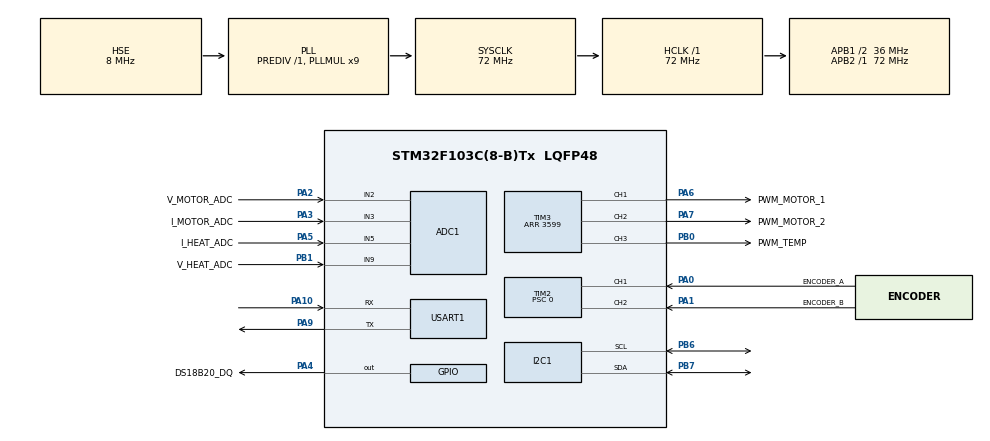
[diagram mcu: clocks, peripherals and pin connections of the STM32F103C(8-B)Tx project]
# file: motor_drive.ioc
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ADC1.Channel-0\#ChannelRegularConversion=ADC_CHANNEL_2
ADC1.Channel-1\#ChannelRegularConversion=ADC_CHANNEL_3
ADC1.Channel-2\#ChannelRegularConversion=ADC_CHANNEL_5
ADC1.Channel-3\#ChannelRegularConversion=ADC_CHANNEL_9
ADC1.ContinuousConvMode=ENABLE
ADC1.NbrOfConversion=4
ADC1.NbrOfConversionFlag=1
ADC1.Rank-0\#ChannelRegularConversion=1
ADC1.Rank-1\#ChannelRegularConversion=2
ADC1.Rank-2\#ChannelRegularConversion=3
ADC1.Rank-3\#ChannelRegularConversion=4
ADC1.SamplingTime-0\#ChannelRegularConversion=ADC_SAMPLETIME_71CYCLES_5
ADC1.SamplingTime-1\#ChannelRegularConversion=ADC_SAMPLETIME_71CYCLES_5
ADC1.SamplingTime-2\#ChannelRegularConversion=ADC_SAMPLETIME_71CYCLES_5
ADC1.SamplingTime-3\#ChannelRegularConversion=ADC_SAMPLETIME_71CYCLES_5
ADC1.master=1
Dma.ADC1.0.Direction=DMA_PERIPH_TO_MEMORY
Dma.ADC1.0.Instance=DMA1_Channel1
Dma.ADC1.0.MemDataAlignment=DMA_MDATAALIGN_HALFWORD
Dma.ADC1.0.MemInc=DMA_MINC_ENABLE
Dma.ADC1.0.Mode=DMA_CIRCULAR
Dma.ADC1.0.PeriphDataAlignment=DMA_PDATAALIGN_HALFWORD
Dma.ADC1.0.PeriphInc=DMA_PINC_DISABLE
Dma.ADC1.0.Priority=DMA_PRIORITY_LOW
Dma.Request0=ADC1
FREERTOS.Tasks01=defaultTask,24,128,StartDefaultTask,Default,NULL,Dynamic,NULL,NULL
FREERTOS.configTOTAL_HEAP_SIZE=8192
I2C1.I2C_Mode=I2C_Fast
Mcu.Family=STM32F1
Mcu.Name=STM32F103C(8-B)Tx
Mcu.Package=LQFP48
NVIC.DMA1_Channel1_IRQn=true\:5\:0\:false\:false\:true\:true\:false\:true\:true
NVIC.I2C1_ER_IRQn=true\:5\:0\:false\:false\:true\:true\:true\:true\:true
NVIC.I2C1_EV_IRQn=true\:5\:0\:false\:false\:true\:true\:true\:true\:true
NVIC.PriorityGroup=NVIC_PRIORITYGROUP_4
NVIC.TIM1_UP_IRQn=true\:15\:0\:false\:false\:true\:false\:false\:true\:true
NVIC.TimeBase=TIM1_UP_IRQn
NVIC.TimeBaseIP=TIM1
PA0-WKUP.GPIO_Label=ENCODER_A
PA0-WKUP.GPIO_PuPd=GPIO_PULLUP
PA0-WKUP.Signal=S_TIM2_CH1_ETR
PA1.GPIO_Label=ENCODER_B
PA1.GPIO_PuPd=GPIO_PULLUP
PA1.Signal=S_TIM2_CH2
PA10.Mode=Asynchronous
PA10.Signal=USART1_RX
PA13.Mode=Serial_Wire
PA13.Signal=SYS_JTMS-SWDIO
PA14.Mode=Serial_Wire
PA14.Signal=SYS_JTCK-SWCLK
PA2.GPIO_Label=V_MOTOR_ADC
PA2.Signal=ADCx_IN2
PA3.GPIO_Label=I_MOTOR_ADC
PA3.Signal=ADCx_IN3
PA4.GPIO_Label=DS18B20_DQ
PA4.GPIO_ModeDefaultOutputPP=GPIO_MODE_OUTPUT_OD
PA4.GPIO_PuPd=GPIO_NOPULL
PA4.GPIO_Speed=GPIO_SPEED_FREQ_MEDIUM
PA4.PinState=GPIO_PIN_SET
PA4.Signal=GPIO_Output
PA5.GPIO_Label=I_HEAT_ADC
PA5.Signal=ADCx_IN5
PA6.GPIO_Label=PWM_MOTOR_1
PA6.Signal=S_TIM3_CH1
PA7.GPIO_Label=PWM_MOTOR_2
PA7.Signal=S_TIM3_CH2
PA9.Mode=Asynchronous
PA9.Signal=USART1_TX
PB0.GPIO_Label=PWM_TEMP
PB0.Signal=S_TIM3_CH3
PB1.GPIO_Label=V_HEAT_ADC
PB1.Signal=ADCx_IN9
PB6.Mode=I2C
PB6.Signal=I2C1_SCL
PB7.Mode=I2C
PB7.Signal=I2C1_SDA
PD0-OSC_IN.Mode=HSE-External-Oscillator
PD0-OSC_IN.Signal=RCC_OSC_IN
PD1-OSC_OUT.Mode=HSE-External-Oscillator
PD1-OSC_OUT.Signal=RCC_OSC_OUT
ProjectManager.HeapSize=0x200
ProjectManager.StackSize=0x400
ProjectManager.TargetToolchain=CMake
RCC.ADCPresc=RCC_ADCPCLK2_DIV6
RCC.AHBFreq_Value=72000000
RCC.APB1CLKDivider=RCC_HCLK_DIV2
RCC.APB1Freq_Value=36000000
RCC.APB1TimFreq_Value=72000000
RCC.APB2Freq_Value=72000000
RCC.APB2TimFreq_Value=72000000
RCC.HCLKFreq_Value=72000000
RCC.PLLMUL=RCC_PLL_MUL9
RCC.PLLSourceVirtual=RCC_PLLSOURCE_HSE
RCC.SYSCLKFreq_VALUE=72000000
RCC.SYSCLKSource=RCC_SYSCLKSOURCE_PLLCLK
RCC.USBFreq_Value=72000000
SH.ADCx_IN2.0=ADC1_IN2,IN2
SH.ADCx_IN3.0=ADC2_IN3
SH.ADCx_IN3.1=ADC1_IN3,IN3
SH.ADCx_IN5.0=ADC1_IN5,IN5
SH.ADCx_IN9.0=ADC1_IN9,IN9
SH.S_TIM2_CH1_ETR.0=TIM2_CH1,Encoder_Interface
SH.S_TIM2_CH2.0=TIM2_CH2,Encoder_Interface
SH.S_TIM3_CH1.0=TIM3_CH1,PWM Generation1 CH1
SH.S_TIM3_CH2.0=TIM3_CH2,PWM Generation2 CH2
SH.S_TIM3_CH3.0=TIM3_CH3,PWM Generation3 CH3
TIM2.EncoderMode=TIM_ENCODERMODE_TI12
TIM2.IC1Filter=6
TIM2.IC2Filter=6
TIM2.Period=65535
TIM2.Prescaler=0
TIM3.Channel-PWM\ Generation1\ CH1=TIM_CHANNEL_1
TIM3.Channel-PWM\ Generation2\ CH2=TIM_CHANNEL_2
TIM3.Channel-PWM\ Generation3\ CH3=TIM_CHANNEL_3
TIM3.Period=3599
USART1.VirtualMode=VM_ASYNC
VP_FREERTOS_VS_CMSIS_V2.Mode=CMSIS_V2
VP_SYS_VS_tim1.Mode=TIM1
board=custom

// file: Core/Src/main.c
/* USER CODE BEGIN Header */
/**
  ******************************************************************************
  * @file           : main.c
  * @brief          : Main program body
  ******************************************************************************
  * @attention
  *
  * Copyright (c) 2026 STMicroelectronics.
  * All rights reserved.
  *
  * This software is licensed under terms that can be found in the LICENSE file
  * in the root directory of this software component.
  * If no LICENSE file comes with this software, it is provided AS-IS.
  *
  ******************************************************************************
  */
/* USER CODE END Header */
#include "main.h"
#include "cmsis_os.h"
#include "adc.h"
#include "dma.h"
#include "i2c.h"
#include "tim.h"
#include "usart.h"
#include "gpio.h"

void SystemClock_Config(void);
void MX_FREERTOS_Init(void);

int main(void)
{

  /* MCU Configuration--------------------------------------------------------*/

  /* Reset of all peripherals, Initializes the Flash interface and the Systick. */
  HAL_Init();

  /* Configure the system clock */
  SystemClock_Config();

  /* Initialize all configured peripherals */
  MX_GPIO_Init();
  MX_DMA_Init();
  MX_I2C1_Init();
  MX_TIM2_Init();
  MX_USART1_UART_Init();
  MX_TIM3_Init();
  MX_ADC1_Init();

  /* Init scheduler */
  osKernelInitialize();  /* Call init function for freertos objects (in cmsis_os2.c) */
  MX_FREERTOS_Init();

  /* Start scheduler */
  osKernelStart();

  /* We should never get here as control is now taken by the scheduler */

  /* Infinite loop */
  while (1)
  {

  }
}

void SystemClock_Config(void)
{
  RCC_OscInitTypeDef RCC_OscInitStruct = {0};
  RCC_ClkInitTypeDef RCC_ClkInitStruct = {0};
  RCC_PeriphCLKInitTypeDef PeriphClkInit = {0};

  /** Initializes the RCC Oscillators according to the specified parameters
  * in the RCC_OscInitTypeDef structure.
  */
  RCC_OscInitStruct.OscillatorType = RCC_OSCILLATORTYPE_HSE;
  RCC_OscInitStruct.HSEState = RCC_HSE_ON;
  RCC_OscInitStruct.HSEPredivValue = RCC_HSE_PREDIV_DIV1;
  RCC_OscInitStruct.HSIState = RCC_HSI_ON;
  RCC_OscInitStruct.PLL.PLLState = RCC_PLL_ON;
  RCC_OscInitStruct.PLL.PLLSource = RCC_PLLSOURCE_HSE;
  RCC_OscInitStruct.PLL.PLLMUL = RCC_PLL_MUL9;
  if (HAL_RCC_OscConfig(&RCC_OscInitStruct) != HAL_OK)
  {
    Error_Handler();
  }

  /** Initializes the CPU, AHB and APB buses clocks
  */
  RCC_ClkInitStruct.ClockType = RCC_CLOCKTYPE_HCLK|RCC_CLOCKTYPE_SYSCLK
                              |RCC_CLOCKTYPE_PCLK1|RCC_CLOCKTYPE_PCLK2;
  RCC_ClkInitStruct.SYSCLKSource = RCC_SYSCLKSOURCE_PLLCLK;
  RCC_ClkInitStruct.AHBCLKDivider = RCC_SYSCLK_DIV1;
  RCC_ClkInitStruct.APB1CLKDivider = RCC_HCLK_DIV2;
  RCC_ClkInitStruct.APB2CLKDivider = RCC_HCLK_DIV1;

  if (HAL_RCC_ClockConfig(&RCC_ClkInitStruct, FLASH_LATENCY_2) != HAL_OK)
  {
    Error_Handler();
  }
  PeriphClkInit.PeriphClockSelection = RCC_PERIPHCLK_ADC;
  PeriphClkInit.AdcClockSelection = RCC_ADCPCLK2_DIV6;
  if (HAL_RCCEx_PeriphCLKConfig(&PeriphClkInit) != HAL_OK)
  {
    Error_Handler();
  }
}

void HAL_TIM_PeriodElapsedCallback(TIM_HandleTypeDef *htim)
{
  if (htim->Instance == TIM1)
  {
    HAL_IncTick();
  }
}

void Error_Handler(void)
{
  __disable_irq();
  while (1)
  {
  }
}

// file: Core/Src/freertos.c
/* USER CODE BEGIN Header */
/**
  ******************************************************************************
  * File Name          : freertos.c
  * Description        : Code for freertos applications
  ******************************************************************************
  * @attention
  *
  * Copyright (c) 2026 STMicroelectronics.
  * All rights reserved.
  *
  * This software is licensed under terms that can be found in the LICENSE file
  * in the root directory of this software component.
  * If no LICENSE file comes with this software, it is provided AS-IS.
  *
  ******************************************************************************
  */
/* USER CODE END Header */

#include "FreeRTOS.h"
#include "task.h"
#include "main.h"
#include "cmsis_os.h"

/* USER CODE BEGIN Includes */

#include "app_main.h"

/* USER CODE END Includes */

/* Definitions for defaultTask */
osThreadId_t defaultTaskHandle;
const osThreadAttr_t defaultTask_attributes = {
  .name = "defaultTask",
  .stack_size = 128 * 4,
  .priority = (osPriority_t) osPriorityNormal,
};

void StartDefaultTask(void *argument);

void MX_FREERTOS_Init(void); /* (MISRA C 2004 rule 8.1) */

void MX_FREERTOS_Init(void) {

  /* Create the thread(s) */
  /* creation of defaultTask */
  defaultTaskHandle = osThreadNew(StartDefaultTask, NULL, &defaultTask_attributes);

}

void StartDefaultTask(void *argument)
{
  /* USER CODE BEGIN StartDefaultTask */
  /* 启动任务：完成应用层初始化、创建各业务任务后自行退出。
     进入调度循环后的所有工作都在 App/ 下的任务中完成，
     本任务不再参与运行。                                        */
  App_Init();
  osThreadExit();
  /* USER CODE END StartDefaultTask */
}
